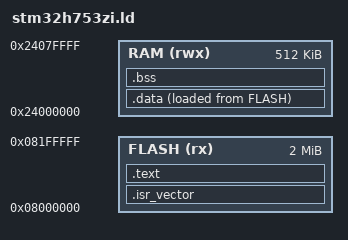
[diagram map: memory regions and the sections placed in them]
/* NUCLEO-H753ZI / STM32H753ZI memory map. */
ENTRY(Reset_Handler)

_estack = ORIGIN(RAM) + LENGTH(RAM);

MEMORY
{
    FLASH (rx)  : ORIGIN = 0x08000000, LENGTH = 2048K
    RAM   (rwx) : ORIGIN = 0x24000000, LENGTH = 512K
}

SECTIONS
{
    .isr_vector :
    {
        . = ALIGN(4);
        KEEP(*(.isr_vector))
        . = ALIGN(4);
    } > FLASH

    .text :
    {
        . = ALIGN(4);
        *(.text*)
        *(.rodata*)
        . = ALIGN(4);
        _etext = .;
    } > FLASH

    _sidata = LOADADDR(.data);

    .data :
    {
        . = ALIGN(4);
        _sdata = .;
        *(.data*)
        . = ALIGN(4);
        _edata = .;
    } > RAM AT > FLASH

    .bss :
    {
        . = ALIGN(4);
        _sbss = .;
        *(.bss*)
        *(COMMON)
        . = ALIGN(4);
        _ebss = .;
    } > RAM

    . = ALIGN(8);
    PROVIDE(end = .);
    PROVIDE(_end = .);

    /DISCARD/ :
    {
        *libc.a:* (*);
        *libm.a:* (*);
        *libgcc.a:* (__aeabi_f2d __aeabi_d2f __aeabi_fmul __aeabi_dmul);
    }
}
